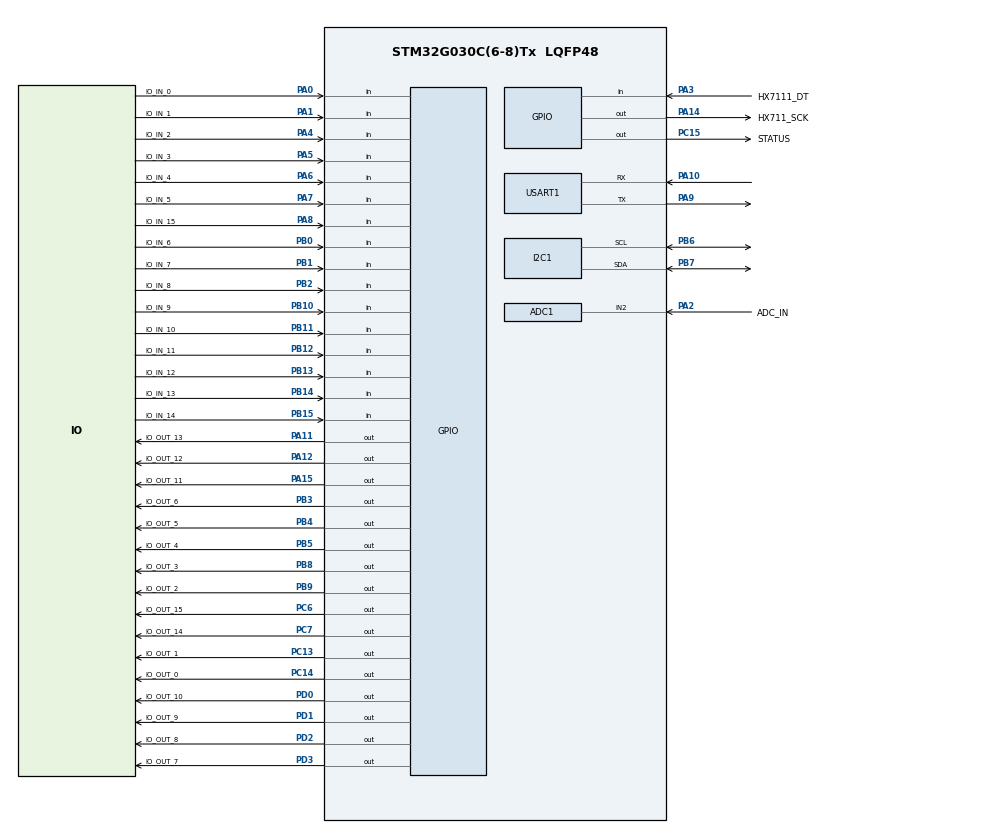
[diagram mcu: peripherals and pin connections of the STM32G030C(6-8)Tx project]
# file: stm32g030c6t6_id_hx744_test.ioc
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ADC1.Channel-0\#ChannelRegularConversion=ADC_CHANNEL_2
ADC1.ClockPrescaler=ADC_CLOCK_SYNC_PCLK_DIV2
ADC1.ContinuousConvMode=DISABLE
ADC1.DMAContinuousRequests=DISABLE
ADC1.NbrOfConversionFlag=1
ADC1.Rank-0\#ChannelRegularConversion=1
ADC1.SamplingTime-0\#ChannelRegularConversion=ADC_SAMPLINGTIME_COMMON_1
ADC1.SamplingTimeCommon1=ADC_SAMPLETIME_12CYCLES_5
ADC1.SelectedChannel=ADC_CHANNEL_2
ADC1.master=1
Dma.I2C1_RX.1.Direction=DMA_PERIPH_TO_MEMORY
Dma.I2C1_RX.1.EventEnable=DISABLE
Dma.I2C1_RX.1.Instance=DMA1_Channel3
Dma.I2C1_RX.1.MemDataAlignment=DMA_MDATAALIGN_BYTE
Dma.I2C1_RX.1.MemInc=DMA_MINC_ENABLE
Dma.I2C1_RX.1.Mode=DMA_NORMAL
Dma.I2C1_RX.1.PeriphDataAlignment=DMA_PDATAALIGN_BYTE
Dma.I2C1_RX.1.PeriphInc=DMA_PINC_DISABLE
Dma.I2C1_RX.1.Polarity=HAL_DMAMUX_REQ_GEN_RISING
Dma.I2C1_RX.1.Priority=DMA_PRIORITY_LOW
Dma.I2C1_RX.1.RequestNumber=1
Dma.I2C1_RX.1.SignalID=NONE
Dma.I2C1_RX.1.SyncEnable=DISABLE
Dma.I2C1_RX.1.SyncPolarity=HAL_DMAMUX_SYNC_NO_EVENT
Dma.I2C1_RX.1.SyncRequestNumber=1
Dma.I2C1_RX.1.SyncSignalID=NONE
Dma.Request0=USART1_RX
Dma.Request1=I2C1_RX
Dma.Request2=USART1_TX
Dma.USART1_RX.0.Direction=DMA_PERIPH_TO_MEMORY
Dma.USART1_RX.0.EventEnable=DISABLE
Dma.USART1_RX.0.Instance=DMA1_Channel1
Dma.USART1_RX.0.MemDataAlignment=DMA_MDATAALIGN_BYTE
Dma.USART1_RX.0.MemInc=DMA_MINC_ENABLE
Dma.USART1_RX.0.Mode=DMA_CIRCULAR
Dma.USART1_RX.0.PeriphDataAlignment=DMA_PDATAALIGN_BYTE
Dma.USART1_RX.0.PeriphInc=DMA_PINC_DISABLE
Dma.USART1_RX.0.Polarity=HAL_DMAMUX_REQ_GEN_RISING
Dma.USART1_RX.0.Priority=DMA_PRIORITY_LOW
Dma.USART1_RX.0.RequestNumber=1
Dma.USART1_RX.0.SignalID=NONE
Dma.USART1_RX.0.SyncEnable=DISABLE
Dma.USART1_RX.0.SyncPolarity=HAL_DMAMUX_SYNC_NO_EVENT
Dma.USART1_RX.0.SyncRequestNumber=1
Dma.USART1_RX.0.SyncSignalID=NONE
Dma.USART1_TX.2.Direction=DMA_MEMORY_TO_PERIPH
Dma.USART1_TX.2.EventEnable=DISABLE
Dma.USART1_TX.2.Instance=DMA1_Channel2
Dma.USART1_TX.2.MemDataAlignment=DMA_MDATAALIGN_BYTE
Dma.USART1_TX.2.MemInc=DMA_MINC_ENABLE
Dma.USART1_TX.2.Mode=DMA_NORMAL
Dma.USART1_TX.2.PeriphDataAlignment=DMA_PDATAALIGN_BYTE
Dma.USART1_TX.2.PeriphInc=DMA_PINC_DISABLE
Dma.USART1_TX.2.Polarity=HAL_DMAMUX_REQ_GEN_RISING
Dma.USART1_TX.2.Priority=DMA_PRIORITY_LOW
Dma.USART1_TX.2.RequestNumber=1
Dma.USART1_TX.2.SignalID=NONE
Dma.USART1_TX.2.SyncEnable=DISABLE
Dma.USART1_TX.2.SyncPolarity=HAL_DMAMUX_SYNC_NO_EVENT
Dma.USART1_TX.2.SyncRequestNumber=1
Dma.USART1_TX.2.SyncSignalID=NONE
I2C1.Timing=0x10707DBC
IWDG.Prescaler=IWDG_PRESCALER_32
Mcu.Family=STM32G0
Mcu.Name=STM32G030C(6-8)Tx
Mcu.Package=LQFP48
NVIC.DMA1_Channel1_IRQn=true\:2\:0\:true\:false\:true\:false\:true\:true
NVIC.DMA1_Channel2_3_IRQn=true\:2\:0\:true\:false\:true\:false\:true\:true
NVIC.I2C1_IRQn=true\:3\:0\:true\:false\:true\:true\:true\:true
NVIC.TIM14_IRQn=true\:3\:0\:true\:false\:true\:true\:true\:true
NVIC.TIM16_IRQn=true\:3\:0\:true\:false\:true\:true\:true\:true
NVIC.TIM17_IRQn=true\:3\:0\:true\:false\:true\:true\:true\:true
NVIC.TIM3_IRQn=true\:3\:0\:true\:false\:true\:true\:true\:true
NVIC.USART1_IRQn=true\:2\:0\:true\:false\:true\:true\:true\:true
PA0.GPIO_Label=IO_IN_0
PA0.GPIO_PuPd=GPIO_PULLUP
PA0.Signal=GPIO_Input
PA1.GPIO_Label=IO_IN_1
PA1.GPIO_PuPd=GPIO_PULLUP
PA1.Signal=GPIO_Input
PA10.Mode=Asynchronous
PA10.Signal=USART1_RX
PA11\ [PA9].GPIO_Label=IO_OUT_13
PA11\ [PA9].Signal=GPIO_Output
PA12\ [PA10].GPIO_Label=IO_OUT_12
PA12\ [PA10].Signal=GPIO_Output
PA14-BOOT0.GPIO_Label=HX711_SCK
PA14-BOOT0.GPIO_Speed=GPIO_SPEED_FREQ_HIGH
PA14-BOOT0.PinState=GPIO_PIN_SET
PA14-BOOT0.Signal=GPIO_Output
PA15.GPIO_Label=IO_OUT_11
PA15.Signal=GPIO_Output
PA2.GPIO_Label=ADC_IN
PA2.Mode=IN2
PA2.Signal=ADC1_IN2
PA3.GPIO_Label=HX7111_DT
PA3.Signal=GPIO_Input
PA4.GPIO_Label=IO_IN_2
PA4.GPIO_PuPd=GPIO_PULLUP
PA4.Signal=GPIO_Input
PA5.GPIO_Label=IO_IN_3
PA5.GPIO_PuPd=GPIO_PULLUP
PA5.Signal=GPIO_Input
PA6.GPIO_Label=IO_IN_4
PA6.GPIO_PuPd=GPIO_PULLUP
PA6.Signal=GPIO_Input
PA7.GPIO_Label=IO_IN_5
PA7.GPIO_PuPd=GPIO_PULLUP
PA7.Signal=GPIO_Input
PA8.GPIO_Label=IO_IN_15
PA8.GPIO_PuPd=GPIO_PULLUP
PA8.Signal=GPIO_Input
PA9.Mode=Asynchronous
PA9.Signal=USART1_TX
PB0.GPIO_Label=IO_IN_6
PB0.GPIO_PuPd=GPIO_PULLUP
PB0.Signal=GPIO_Input
PB1.GPIO_Label=IO_IN_7
PB1.GPIO_PuPd=GPIO_PULLUP
PB1.Signal=GPIO_Input
PB10.GPIO_Label=IO_IN_9
PB10.GPIO_PuPd=GPIO_PULLUP
PB10.Signal=GPIO_Input
PB11.GPIO_Label=IO_IN_10
PB11.GPIO_PuPd=GPIO_PULLUP
PB11.Signal=GPIO_Input
PB12.GPIO_Label=IO_IN_11
PB12.GPIO_PuPd=GPIO_PULLUP
PB12.Signal=GPIO_Input
PB13.GPIO_Label=IO_IN_12
PB13.GPIO_PuPd=GPIO_PULLUP
PB13.Signal=GPIO_Input
PB14.GPIO_Label=IO_IN_13
PB14.GPIO_PuPd=GPIO_PULLUP
PB14.Signal=GPIO_Input
PB15.GPIO_Label=IO_IN_14
PB15.GPIO_PuPd=GPIO_PULLUP
PB15.Signal=GPIO_Input
PB2.GPIO_Label=IO_IN_8
PB2.GPIO_PuPd=GPIO_PULLUP
PB2.Signal=GPIO_Input
PB3.GPIO_Label=IO_OUT_6
PB3.Signal=GPIO_Output
PB4.GPIO_Label=IO_OUT_5
PB4.Signal=GPIO_Output
PB5.GPIO_Label=IO_OUT_4
PB5.Signal=GPIO_Output
PB6.Mode=I2C
PB6.Signal=I2C1_SCL
PB7.Mode=I2C
PB7.Signal=I2C1_SDA
PB8.GPIO_Label=IO_OUT_3
PB8.Signal=GPIO_Output
PB9.GPIO_Label=IO_OUT_2
PB9.Signal=GPIO_Output
PC13.GPIO_Label=IO_OUT_1
PC13.Signal=GPIO_Output
PC14-OSC32_IN\ (PC14).GPIO_Label=IO_OUT_0
PC14-OSC32_IN\ (PC14).Signal=GPIO_Output
PC15-OSC32_OUT\ (PC15).GPIO_Label=STATUS
PC15-OSC32_OUT\ (PC15).GPIO_PuPd=GPIO_PULLUP
PC15-OSC32_OUT\ (PC15).Signal=GPIO_Output
PC6.GPIO_Label=IO_OUT_15
PC6.Signal=GPIO_Output
PC7.GPIO_Label=IO_OUT_14
PC7.Signal=GPIO_Output
PD0.GPIO_Label=IO_OUT_10
PD0.Signal=GPIO_Output
PD1.GPIO_Label=IO_OUT_9
PD1.Signal=GPIO_Output
PD2.GPIO_Label=IO_OUT_8
PD2.Signal=GPIO_Output
PD3.GPIO_Label=IO_OUT_7
PD3.Signal=GPIO_Output
PF0-OSC_IN\ (PF0).Mode=HSE-External-Oscillator
PF0-OSC_IN\ (PF0).Signal=RCC_OSC_IN
PF1-OSC_OUT\ (PF1).Mode=HSE-External-Oscillator
PF1-OSC_OUT\ (PF1).Signal=RCC_OSC_OUT
ProjectManager.HeapSize=0x200
ProjectManager.StackSize=0x400
ProjectManager.TargetToolchain=STM32CubeIDE
RCC.ADCFreq_Value=64000000
RCC.AHBFreq_Value=64000000
RCC.CortexFreq_Value=64000000
RCC.EXTERNAL_CLOCK_VALUE=12288000
RCC.HCLKFreq_Value=64000000
RCC.HSE_VALUE=8000000
RCC.HSI_VALUE=16000000
RCC.LSE_VALUE=32768
RCC.PLLN=16
RCC.PLLSourceVirtual=RCC_PLLSOURCE_HSE
RCC.SYSCLKFreq_VALUE=64000000
RCC.SYSCLKSource=RCC_SYSCLKSOURCE_PLLCLK
RCC.VCOOutputFreq_Value=128000000
TIM3.Prescaler=62-1
USART1.VirtualMode-Asynchronous=VM_ASYNC
VP_IWDG_VS_IWDG.Mode=IWDG_Activate
VP_TIM14_VS_ClockSourceINT.Mode=Enable_Timer
VP_TIM16_VS_ClockSourceINT.Mode=Enable_Timer
VP_TIM17_VS_ClockSourceINT.Mode=Enable_Timer
VP_TIM3_VS_ClockSourceINT.Mode=Internal
board=custom

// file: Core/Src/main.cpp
/*
 * main.cpp
 *
 *  Created on: Jul 7, 2023
 *      Author: gns2l
 */

#include "main.h"
#include "ap.hpp"

ADC_HandleTypeDef hadc1;

I2C_HandleTypeDef hi2c1;
DMA_HandleTypeDef hdma_i2c1_rx;

IWDG_HandleTypeDef hiwdg;

TIM_HandleTypeDef htim3;
TIM_HandleTypeDef htim14;
TIM_HandleTypeDef htim16;
TIM_HandleTypeDef htim17;

UART_HandleTypeDef huart1;
DMA_HandleTypeDef hdma_usart1_rx;
DMA_HandleTypeDef hdma_usart1_tx;

void SystemClock_Config(void);
static void MX_GPIO_Init(void);
static void MX_DMA_Init(void);
static void MX_USART1_UART_Init(void);
static void MX_I2C1_Init(void);
static void MX_TIM3_Init(void);
static void MX_TIM14_Init(void);
static void MX_TIM16_Init(void);
static void MX_IWDG_Init(void);
static void MX_ADC1_Init(void);
static void MX_TIM17_Init(void);

int main(void)
{
  HAL_Init();

  SystemClock_Config();

  MX_GPIO_Init();
  MX_DMA_Init();
  MX_USART1_UART_Init();
  MX_I2C1_Init();
  MX_TIM3_Init();
  MX_TIM14_Init();
  MX_TIM16_Init();
  MX_IWDG_Init();
  MX_ADC1_Init();
  MX_TIM17_Init();

  bspInit();
  hwInit();
  exhwInit();
  apInit();
  apMain();

  HAL_GPIO_WritePin(STATUS_GPIO_Port, STATUS_Pin, GPIO_PIN_SET);

  HAL_GPIO_WritePin(STATUS_GPIO_Port, STATUS_Pin, GPIO_PIN_RESET);

  while (1)
  {

    HAL_GPIO_TogglePin(STATUS_GPIO_Port, STATUS_Pin);

    HAL_Delay(300);
  }
}

void SystemClock_Config(void)
{
  LL_FLASH_SetLatency(LL_FLASH_LATENCY_2);
  while(LL_FLASH_GetLatency() != LL_FLASH_LATENCY_2)
  {
  }

  /* HSE configuration and activation */
  LL_RCC_HSE_Enable();
  while(LL_RCC_HSE_IsReady() != 1)
  {
  }

  /* LSI configuration and activation */
  LL_RCC_LSI_Enable();
  while(LL_RCC_LSI_IsReady() != 1)
  {
  }

  /* Main PLL configuration and activation */
  LL_RCC_PLL_ConfigDomain_SYS(LL_RCC_PLLSOURCE_HSE, LL_RCC_PLLM_DIV_1, 16, LL_RCC_PLLR_DIV_2);
  LL_RCC_PLL_Enable();
  LL_RCC_PLL_EnableDomain_SYS();
  while(LL_RCC_PLL_IsReady() != 1)
  {
  }

  /* Set AHB prescaler*/
  LL_RCC_SetAHBPrescaler(LL_RCC_SYSCLK_DIV_1);

  /* Sysclk activation on the main PLL */
  LL_RCC_SetSysClkSource(LL_RCC_SYS_CLKSOURCE_PLL);
  while(LL_RCC_GetSysClkSource() != LL_RCC_SYS_CLKSOURCE_STATUS_PLL)
  {
  }

  /* Set APB1 prescaler*/
  LL_RCC_SetAPB1Prescaler(LL_RCC_APB1_DIV_1);
  /* Update CMSIS variable (which can be updated also through SystemCoreClockUpdate function) */
  LL_SetSystemCoreClock(64000000);

   /* Update the time base */
  if (HAL_InitTick (TICK_INT_PRIORITY) != HAL_OK)
  {
    Error_Handler();
  }
}

static void MX_ADC1_Init(void)
{

  ADC_ChannelConfTypeDef sConfig = {0};

  /** Configure the global features of the ADC (Clock, Resolution, Data Alignment and number of conversion)
  */
  hadc1.Instance = ADC1;
  hadc1.Init.ClockPrescaler = ADC_CLOCK_SYNC_PCLK_DIV2;
  hadc1.Init.Resolution = ADC_RESOLUTION_12B;
  hadc1.Init.DataAlign = ADC_DATAALIGN_RIGHT;
  hadc1.Init.ScanConvMode = ADC_SCAN_DISABLE;
  hadc1.Init.EOCSelection = ADC_EOC_SINGLE_CONV;
  hadc1.Init.LowPowerAutoWait = DISABLE;
  hadc1.Init.LowPowerAutoPowerOff = DISABLE;
  hadc1.Init.ContinuousConvMode = DISABLE;
  hadc1.Init.NbrOfConversion = 1;
  hadc1.Init.DiscontinuousConvMode = DISABLE;
  hadc1.Init.ExternalTrigConv = ADC_SOFTWARE_START;
  hadc1.Init.ExternalTrigConvEdge = ADC_EXTERNALTRIGCONVEDGE_NONE;
  hadc1.Init.DMAContinuousRequests = DISABLE;
  hadc1.Init.Overrun = ADC_OVR_DATA_PRESERVED;
  hadc1.Init.SamplingTimeCommon1 = ADC_SAMPLETIME_12CYCLES_5;
  hadc1.Init.SamplingTimeCommon2 = ADC_SAMPLETIME_1CYCLE_5;
  hadc1.Init.OversamplingMode = DISABLE;
  hadc1.Init.TriggerFrequencyMode = ADC_TRIGGER_FREQ_HIGH;
  if (HAL_ADC_Init(&hadc1) != HAL_OK)
  {
    Error_Handler();
  }

  /** Configure Regular Channel
  */
  sConfig.Channel = ADC_CHANNEL_2;
  sConfig.Rank = ADC_REGULAR_RANK_1;
  sConfig.SamplingTime = ADC_SAMPLINGTIME_COMMON_1;
  if (HAL_ADC_ConfigChannel(&hadc1, &sConfig) != HAL_OK)
  {
    Error_Handler();
  }

}

static void MX_I2C1_Init(void)
{

  hi2c1.Instance = I2C1;
  hi2c1.Init.Timing = 0x10707DBC;
  hi2c1.Init.OwnAddress1 = 0;
  hi2c1.Init.AddressingMode = I2C_ADDRESSINGMODE_7BIT;
  hi2c1.Init.DualAddressMode = I2C_DUALADDRESS_DISABLE;
  hi2c1.Init.OwnAddress2 = 0;
  hi2c1.Init.OwnAddress2Masks = I2C_OA2_NOMASK;
  hi2c1.Init.GeneralCallMode = I2C_GENERALCALL_DISABLE;
  hi2c1.Init.NoStretchMode = I2C_NOSTRETCH_DISABLE;
  if (HAL_I2C_Init(&hi2c1) != HAL_OK)
  {
    Error_Handler();
  }

  /** Configure Analogue filter
  */
  if (HAL_I2CEx_ConfigAnalogFilter(&hi2c1, I2C_ANALOGFILTER_ENABLE) != HAL_OK)
  {
    Error_Handler();
  }

  /** Configure Digital filter
  */
  if (HAL_I2CEx_ConfigDigitalFilter(&hi2c1, 0) != HAL_OK)
  {
    Error_Handler();
  }

}

static void MX_IWDG_Init(void)
{

  /* USER CODE BEGIN IWDG_Init 0 */
#if 0
  /* USER CODE END IWDG_Init 0 */

  hiwdg.Instance = IWDG;
  hiwdg.Init.Prescaler = IWDG_PRESCALER_32;
  hiwdg.Init.Window = 4095;
  hiwdg.Init.Reload = 4095;
  if (HAL_IWDG_Init(&hiwdg) != HAL_OK)
  {
    Error_Handler();
  }
  /* USER CODE BEGIN IWDG_Init 2 */
#endif
  /* USER CODE END IWDG_Init 2 */

}

static void MX_TIM3_Init(void)
{

  TIM_ClockConfigTypeDef sClockSourceConfig = {0};
  TIM_MasterConfigTypeDef sMasterConfig = {0};

  htim3.Instance = TIM3;
  htim3.Init.Prescaler = 62-1;
  htim3.Init.CounterMode = TIM_COUNTERMODE_UP;
  htim3.Init.Period = 65535;
  htim3.Init.ClockDivision = TIM_CLOCKDIVISION_DIV1;
  htim3.Init.AutoReloadPreload = TIM_AUTORELOAD_PRELOAD_DISABLE;
  if (HAL_TIM_Base_Init(&htim3) != HAL_OK)
  {
    Error_Handler();
  }
  sClockSourceConfig.ClockSource = TIM_CLOCKSOURCE_INTERNAL;
  if (HAL_TIM_ConfigClockSource(&htim3, &sClockSourceConfig) != HAL_OK)
  {
    Error_Handler();
  }
  sMasterConfig.MasterOutputTrigger = TIM_TRGO_RESET;
  sMasterConfig.MasterSlaveMode = TIM_MASTERSLAVEMODE_DISABLE;
  if (HAL_TIMEx_MasterConfigSynchronization(&htim3, &sMasterConfig) != HAL_OK)
  {
    Error_Handler();
  }

}

static void MX_TIM14_Init(void)
{

  htim14.Instance = TIM14;
  htim14.Init.Prescaler = 0;
  htim14.Init.CounterMode = TIM_COUNTERMODE_UP;
  htim14.Init.Period = 65535;
  htim14.Init.ClockDivision = TIM_CLOCKDIVISION_DIV1;
  htim14.Init.AutoReloadPreload = TIM_AUTORELOAD_PRELOAD_DISABLE;
  if (HAL_TIM_Base_Init(&htim14) != HAL_OK)
  {
    Error_Handler();
  }

}

static void MX_TIM16_Init(void)
{

  htim16.Instance = TIM16;
  htim16.Init.Prescaler = 0;
  htim16.Init.CounterMode = TIM_COUNTERMODE_UP;
  htim16.Init.Period = 65535;
  htim16.Init.ClockDivision = TIM_CLOCKDIVISION_DIV1;
  htim16.Init.RepetitionCounter = 0;
  htim16.Init.AutoReloadPreload = TIM_AUTORELOAD_PRELOAD_DISABLE;
  if (HAL_TIM_Base_Init(&htim16) != HAL_OK)
  {
    Error_Handler();
  }

}

static void MX_TIM17_Init(void)
{

  htim17.Instance = TIM17;
  htim17.Init.Prescaler = 0;
  htim17.Init.CounterMode = TIM_COUNTERMODE_UP;
  htim17.Init.Period = 65535;
  htim17.Init.ClockDivision = TIM_CLOCKDIVISION_DIV1;
  htim17.Init.RepetitionCounter = 0;
  htim17.Init.AutoReloadPreload = TIM_AUTORELOAD_PRELOAD_DISABLE;
  if (HAL_TIM_Base_Init(&htim17) != HAL_OK)
  {
    Error_Handler();
  }

}

static void MX_USART1_UART_Init(void)
{

  huart1.Instance = USART1;
  huart1.Init.BaudRate = 115200;
  huart1.Init.WordLength = UART_WORDLENGTH_8B;
  huart1.Init.StopBits = UART_STOPBITS_1;
  huart1.Init.Parity = UART_PARITY_NONE;
  huart1.Init.Mode = UART_MODE_TX_RX;
  huart1.Init.HwFlowCtl = UART_HWCONTROL_NONE;
  huart1.Init.OverSampling = UART_OVERSAMPLING_16;
  huart1.Init.OneBitSampling = UART_ONE_BIT_SAMPLE_DISABLE;
  huart1.Init.ClockPrescaler = UART_PRESCALER_DIV1;
  huart1.AdvancedInit.AdvFeatureInit = UART_ADVFEATURE_NO_INIT;
  if (HAL_UART_Init(&huart1) != HAL_OK)
  {
    Error_Handler();
  }
  if (HAL_UARTEx_SetTxFifoThreshold(&huart1, UART_TXFIFO_THRESHOLD_1_8) != HAL_OK)
  {
    Error_Handler();
  }
  if (HAL_UARTEx_SetRxFifoThreshold(&huart1, UART_RXFIFO_THRESHOLD_1_8) != HAL_OK)
  {
    Error_Handler();
  }
  if (HAL_UARTEx_DisableFifoMode(&huart1) != HAL_OK)
  {
    Error_Handler();
  }

}

static void MX_DMA_Init(void)
{

  /* DMA controller clock enable */
  __HAL_RCC_DMA1_CLK_ENABLE();

  /* DMA interrupt init */
  /* DMA1_Channel1_IRQn interrupt configuration */
  HAL_NVIC_SetPriority(DMA1_Channel1_IRQn, 2, 0);
  HAL_NVIC_EnableIRQ(DMA1_Channel1_IRQn);
  /* DMA1_Channel2_3_IRQn interrupt configuration */
  HAL_NVIC_SetPriority(DMA1_Channel2_3_IRQn, 2, 0);
  HAL_NVIC_EnableIRQ(DMA1_Channel2_3_IRQn);

}

static void MX_GPIO_Init(void)
{
  GPIO_InitTypeDef GPIO_InitStruct = {0};

  /* GPIO Ports Clock Enable */
  __HAL_RCC_GPIOC_CLK_ENABLE();
  __HAL_RCC_GPIOF_CLK_ENABLE();
  __HAL_RCC_GPIOA_CLK_ENABLE();
  __HAL_RCC_GPIOB_CLK_ENABLE();
  __HAL_RCC_GPIOD_CLK_ENABLE();

  /*Configure GPIO pin Output Level */
  HAL_GPIO_WritePin(GPIOC, IO_OUT_1_Pin|IO_OUT_0_Pin|STATUS_Pin|IO_OUT_15_Pin
                          |IO_OUT_14_Pin, GPIO_PIN_RESET);

  /*Configure GPIO pin Output Level */
  HAL_GPIO_WritePin(GPIOA, IO_OUT_13_Pin|IO_OUT_12_Pin|IO_OUT_11_Pin, GPIO_PIN_RESET);

  /*Configure GPIO pin Output Level */
  HAL_GPIO_WritePin(HX711_SCK_GPIO_Port, HX711_SCK_Pin, GPIO_PIN_SET);

  /*Configure GPIO pin Output Level */
  HAL_GPIO_WritePin(GPIOD, IO_OUT_10_Pin|IO_OUT_9_Pin|IO_OUT_8_Pin|IO_OUT_7_Pin, GPIO_PIN_RESET);

  /*Configure GPIO pin Output Level */
  HAL_GPIO_WritePin(GPIOB, IO_OUT_6_Pin|IO_OUT_5_Pin|IO_OUT_4_Pin|IO_OUT_3_Pin
                          |IO_OUT_2_Pin, GPIO_PIN_RESET);

  /*Configure GPIO pins : IO_OUT_1_Pin IO_OUT_0_Pin IO_OUT_15_Pin IO_OUT_14_Pin */
  GPIO_InitStruct.Pin = IO_OUT_1_Pin|IO_OUT_0_Pin|IO_OUT_15_Pin|IO_OUT_14_Pin;
  GPIO_InitStruct.Mode = GPIO_MODE_OUTPUT_PP;
  GPIO_InitStruct.Pull = GPIO_NOPULL;
  GPIO_InitStruct.Speed = GPIO_SPEED_FREQ_LOW;
  HAL_GPIO_Init(GPIOC, &GPIO_InitStruct);

  /*Configure GPIO pin : STATUS_Pin */
  GPIO_InitStruct.Pin = STATUS_Pin;
  GPIO_InitStruct.Mode = GPIO_MODE_OUTPUT_PP;
  GPIO_InitStruct.Pull = GPIO_PULLUP;
  GPIO_InitStruct.Speed = GPIO_SPEED_FREQ_LOW;
  HAL_GPIO_Init(STATUS_GPIO_Port, &GPIO_InitStruct);

  /*Configure GPIO pins : IO_IN_0_Pin IO_IN_1_Pin IO_IN_2_Pin IO_IN_3_Pin
                           IO_IN_4_Pin IO_IN_5_Pin IO_IN_15_Pin */
  GPIO_InitStruct.Pin = IO_IN_0_Pin|IO_IN_1_Pin|IO_IN_2_Pin|IO_IN_3_Pin
                          |IO_IN_4_Pin|IO_IN_5_Pin|IO_IN_15_Pin;
  GPIO_InitStruct.Mode = GPIO_MODE_INPUT;
  GPIO_InitStruct.Pull = GPIO_PULLUP;
  HAL_GPIO_Init(GPIOA, &GPIO_InitStruct);

  /*Configure GPIO pin : HX7111_DT_Pin */
  GPIO_InitStruct.Pin = HX7111_DT_Pin;
  GPIO_InitStruct.Mode = GPIO_MODE_INPUT;
  GPIO_InitStruct.Pull = GPIO_NOPULL;
  HAL_GPIO_Init(HX7111_DT_GPIO_Port, &GPIO_InitStruct);

  /*Configure GPIO pins : IO_IN_6_Pin IO_IN_7_Pin IO_IN_8_Pin IO_IN_9_Pin
                           IO_IN_10_Pin IO_IN_11_Pin IO_IN_12_Pin IO_IN_13_Pin
                           IO_IN_14_Pin */
  GPIO_InitStruct.Pin = IO_IN_6_Pin|IO_IN_7_Pin|IO_IN_8_Pin|IO_IN_9_Pin
                          |IO_IN_10_Pin|IO_IN_11_Pin|IO_IN_12_Pin|IO_IN_13_Pin
                          |IO_IN_14_Pin;
  GPIO_InitStruct.Mode = GPIO_MODE_INPUT;
  GPIO_InitStruct.Pull = GPIO_PULLUP;
  HAL_GPIO_Init(GPIOB, &GPIO_InitStruct);

  /*Configure GPIO pins : IO_OUT_13_Pin IO_OUT_12_Pin IO_OUT_11_Pin */
  GPIO_InitStruct.Pin = IO_OUT_13_Pin|IO_OUT_12_Pin|IO_OUT_11_Pin;
  GPIO_InitStruct.Mode = GPIO_MODE_OUTPUT_PP;
  GPIO_InitStruct.Pull = GPIO_NOPULL;
  GPIO_InitStruct.Speed = GPIO_SPEED_FREQ_LOW;
  HAL_GPIO_Init(GPIOA, &GPIO_InitStruct);

  /*Configure GPIO pin : HX711_SCK_Pin */
  GPIO_InitStruct.Pin = HX711_SCK_Pin;
  GPIO_InitStruct.Mode = GPIO_MODE_OUTPUT_PP;
  GPIO_InitStruct.Pull = GPIO_NOPULL;
  GPIO_InitStruct.Speed = GPIO_SPEED_FREQ_HIGH;
  HAL_GPIO_Init(HX711_SCK_GPIO_Port, &GPIO_InitStruct);

  /*Configure GPIO pins : IO_OUT_10_Pin IO_OUT_9_Pin IO_OUT_8_Pin IO_OUT_7_Pin */
  GPIO_InitStruct.Pin = IO_OUT_10_Pin|IO_OUT_9_Pin|IO_OUT_8_Pin|IO_OUT_7_Pin;
  GPIO_InitStruct.Mode = GPIO_MODE_OUTPUT_PP;
  GPIO_InitStruct.Pull = GPIO_NOPULL;
  GPIO_InitStruct.Speed = GPIO_SPEED_FREQ_LOW;
  HAL_GPIO_Init(GPIOD, &GPIO_InitStruct);

  /*Configure GPIO pins : IO_OUT_6_Pin IO_OUT_5_Pin IO_OUT_4_Pin IO_OUT_3_Pin
                           IO_OUT_2_Pin */
  GPIO_InitStruct.Pin = IO_OUT_6_Pin|IO_OUT_5_Pin|IO_OUT_4_Pin|IO_OUT_3_Pin
                          |IO_OUT_2_Pin;
  GPIO_InitStruct.Mode = GPIO_MODE_OUTPUT_PP;
  GPIO_InitStruct.Pull = GPIO_NOPULL;
  GPIO_InitStruct.Speed = GPIO_SPEED_FREQ_LOW;
  HAL_GPIO_Init(GPIOB, &GPIO_InitStruct);

}

void Error_Handler(void)
{
  __disable_irq();
  while (1)
  {
  }
}
